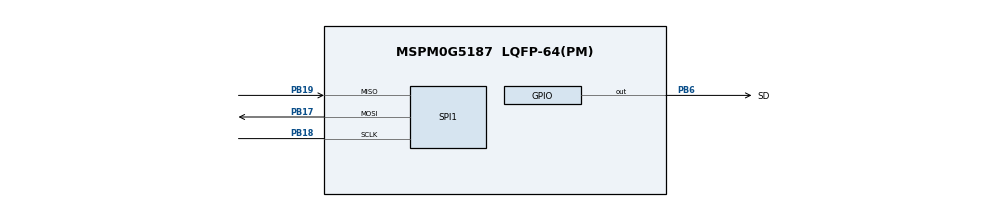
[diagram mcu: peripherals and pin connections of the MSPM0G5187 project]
//@cliArgs --device "MSPM0G518X" --package "LQFP-64(PM)" --part "Default"
//@v2CliArgs --device "MSPM0G5187" --package "LQFP-64(PM)"
// @cliArgs --board /ti/boards/LP_MSPM0G5187 --rtos nortos

/**
 * Import the modules used in this configuration.
 */
const GPIO    = scripting.addModule("/ti/driverlib/GPIO", {}, false);
const GPIO1   = GPIO.addInstance();
const SPI     = scripting.addModule("/ti/driverlib/SPI", {}, false);
const SPI1    = SPI.addInstance();
const SYSCTL  = scripting.addModule("/ti/driverlib/SYSCTL");
const SYSTICK = scripting.addModule("/ti/driverlib/SYSTICK");
const TIMER   = scripting.addModule("/ti/driverlib/TIMER", {}, false);
const TIMER1  = TIMER.addInstance();

/**
 * Write custom configuration values to the imported modules.
 */
GPIO1.$name                              = "SD_CS_GPIO";
GPIO1.port                               = "PORTB";
GPIO1.portSegment                        = "Lower";
GPIO1.associatedPins[0].$name            = "SD";
GPIO1.associatedPins[0].initialValue     = "SET";
GPIO1.associatedPins[0].internalResistor = "PULL_UP";
GPIO1.associatedPins[0].assignedPin      = "6";
GPIO1.associatedPins[0].pin.$assign      = "PB6";

const Board = scripting.addModule("/ti/driverlib/Board", {}, false);

SPI1.frameFormat                        = "MOTO3";
SPI1.$name                              = "SD_SPI";
SPI1.targetBitRate                      = 200000;
SPI1.sclkPinConfig.enableConfig         = true;
SPI1.sclkPinConfig.internalResistor     = "PULL_DOWN";
SPI1.mosiPinConfig.enableConfig         = true;
SPI1.mosiPinConfig.internalResistor     = "PULL_UP";
SPI1.misoPinConfig.enableConfig         = true;
SPI1.misoPinConfig.internalResistor     = "PULL_UP";
SPI1.peripheral.sclkPin.$assign         = "PB18";
SPI1.peripheral.mosiPin.$assign         = "PB17";
SPI1.peripheral.misoPin.$assign         = "PB19";

SYSTICK.periodEnable  = true;
SYSTICK.period        = 32000;
SYSTICK.systickEnable = true;

TIMER1.$name           = "TIMER_0";
TIMER1.timerPeriod     = "1 ms";
TIMER1.timerMode       = "PERIODIC";
TIMER1.timerStartTimer = true;
TIMER1.interrupts      = ["LOAD"];
